# S6E1B3xG register map
Vendor: Cypress; File version: 2.1
CPU: CM0PLUS r0p1, little endian, no MPU, no FPU, 2 interrupt priority bits
Registers are 8-bit, read-write, reset 0x0 unless marked. A register's access mark holds for its fields unless they carry their own. Offsets are from the block's base; [hi:lo] are bit positions; {n}, {i} and the like mark numbered series.

## USBCLK — USB/Ethernet Clock
Base 0x40036000
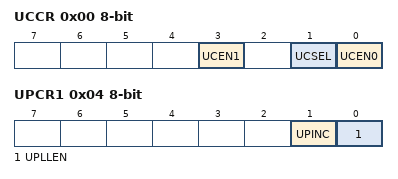
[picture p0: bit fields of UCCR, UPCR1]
0x00 UCCR — USB Clock Control Register [BHW]
  [3] UCEN1 — USB1 clock output enable bit
  [1] UCSEL — USB clock selection bit
  [0] UCEN0 — USB0 clock output enable bit
0x04 UPCR1 — USB-PLL Control Register 1 [BHW]
  [1] UPINC — USB-PLL input clock selection bit
  [0] UPLLEN — USB-PLL oscillation enable bit
0x08 UPCR2 — USB-PLL Control Register 2 [BHW]
  [2:0] UPOWT — USB-PLL oscillation stabilization wait time setting bit
0x0C UPCR3 — USB-PLL Control Register 3 [BHW]
  [4:0] UPLLK — Frequency division ratio (K) setting bit of the USB-PLL clock
0x10 UPCR4 reset 0x3B — USB-PLL Control Register 4 [BHW]
  [6:0] UPLLN — Frequency division ratio (N) setting bit of the USB-PLL clock
0x14 UP_STR ro — USB-PLL Status Register [BHW]
  [0] UPRDY — USB-PLL oscillation stabilization bit
0x18 UPINT_ENR — USB-PLL Interrupt Factor Enable Register [BHW]
  [0] UPCSE — USB-PLL oscillation stabilization wait complete interrupt enable bit
0x1C UPINT_CLR wo — USB-PLL Interrupt Factor Clear Register [BHW]
  [0] UPCSC — USB-PLL oscillation stabilization interrupt factor clear bit
0x20 UPINT_STR ro — USB-PLL Interrupt Factor Status Register [BHW]
  [0] UPCSI — USB-PLL interrupt factor status bit
0x24 UPCR5 reset 0x4 — USB-PLL Control Register 5 [BHW]
  [3:0] UPLLM — Frequency division ratio (M) setting bit of the USB-PLL clock
0x30 USBEN0 reset 0x4 — USB0 Enable Register [BHW]
  [0] USBEN0 — USB0 enable bit
0x34 USBEN1 reset 0x4 — USB1 Enable Register [BHW]
  [0] USBEN1 — USB1 enable bit

## CRC — CRC Registers
Base 0x40039000
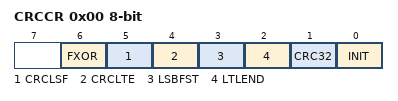
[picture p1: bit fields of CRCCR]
0x00 CRCCR — CRC Control Register [BHW]
  [6] FXOR — Final XOR control bit
  [5] CRCLSF — CRC result bit-order setting bit
  [4] CRCLTE — CRC result byte-order setting bit
  [3] LSBFST — Bit-order setting bit
  [2] LTLEND — Byte-order setting bit
  [1] CRC32 — CRC mode selection bit
  [0] INIT — Initialization bit
0x04 CRCINIT 32-bit reset 0xFFFFFFFF — Initial Value Register [BHW]
  [31:0] D — Initial value bits
0x08 CRCIN 32-bit — Input Data Register [BHW]
  [31:0] D — Input data bits
0x0C CRCR 32-bit ro reset 0xFFFFFFFF — CRC Register [BHW]
  [31:0] D — CRC bits

## WC — Watch Counter
Base 0x4003A000
0x00 WCRD ro — Watch Counter Read Register [BHW]
  [5:0] CTR — Counter read bits
0x01 WCRL — Watch Counter Reload Register [BHW]
  [5:0] RLC — Counter reload value setting bits
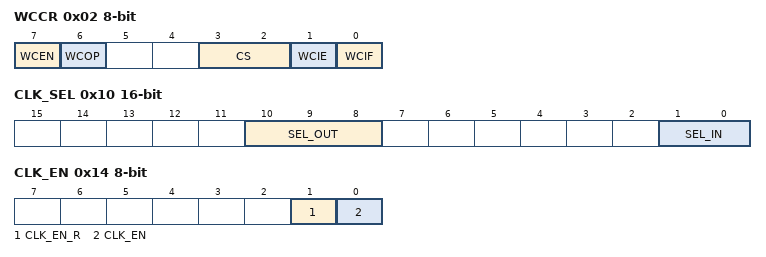
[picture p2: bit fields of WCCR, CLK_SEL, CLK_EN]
0x02 WCCR — Watch Counter Control Register [BHW]
  [7] WCEN — Watch counter operation enable bit
  [6] WCOP ro — Watch counter operating state flag
  [3:2] CS — Count clock select bits
  [1] WCIE — Interrupt request enable bit
  [0] WCIF — Interrupt request flag bit
0x10 CLK_SEL 16-bit — Clock Selection Register [BHW]
  [10:8] SEL_OUT — Output clock selection bit
  [1:0] SEL_IN — Input clock selection bit
0x14 CLK_EN — Division Clock Enable Register [BHW]
  [1] CLK_EN_R — Division clock enable read bit
  [0] CLK_EN — Division clock enable bit

## LSCRP — Low-speed CR Prescaler Register
Base 0x4003C000
0x00 LCR_PRSLD — Low-speed CR Prescaler Control Register [BHW]
  [5:0] LCR_PRSLD — Low-speed CR Prescaler Load

## MFSI2S0 — I2S0 Registers
Base 0x4003CA00
Same registers: MFSI2S1 0x4003CA80
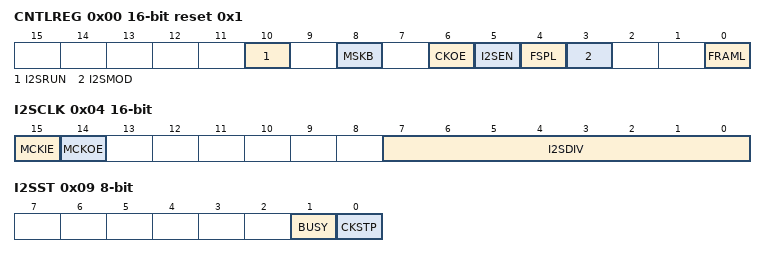
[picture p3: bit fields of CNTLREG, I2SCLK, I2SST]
0x00 CNTLREG 16-bit reset 0x1 — Control Register [HW]
  [10] I2SRUN — I2S clock generate enable bit
  [8] MSKB — Mask bit output bit
  [6] CKOE — I2SCK and I2SWS output enable bit
  [5] I2SEN — I2S mode enable bit
  [4] FSPL — I2SWS polarity set bit
  [3] I2SMOD — I2S mode select bit
  [0] FRAML — Frame length select bit
0x04 I2SCLK 16-bit — I2S Clock Register [HW]
  [15] MCKIE — Main clock input enable bit
  [14] MCKOE — Main clock output enable bit
  [7:0] I2SDIV — I2S clock division set bit
0x08 I2SRST wo — I2S Reset Register [B]
  [7:0] I2SRST — I2S software reset bit
0x09 I2SST ro — I2S Status Register [B]
  [1] BUSY — Bus busy indication for transmit bit
  [0] CKSTP — Clock stop indication bit

## DSTC — DSTC registers
Base 0x40061000
0x00 DESTP 32-bit — Descriptor top address Register [BHW]
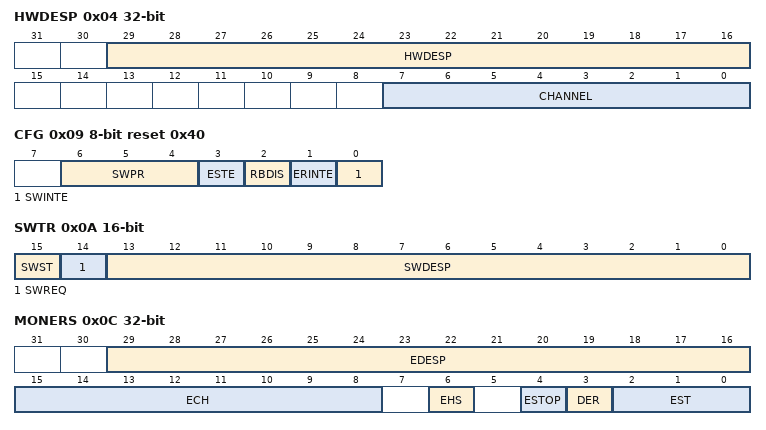
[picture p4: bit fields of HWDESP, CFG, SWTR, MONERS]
0x04 HWDESP 32-bit — Hardware DES pointer Register [BHW]
  [29:16] HWDESP, [7:0] CHANNEL
0x08 CMD reset 0x1 — Command Register [B]
0x09 CFG reset 0x40 — Configuration Register [B]
  [6:4] SWPR — Software transfer priority
  [3] ESTE — Error stop enable
  [2] RBDIS — Read skip buffer disable
  [1] ERINTE — Error interrupt enable
  [0] SWINTE — Software interrupt enable
0x0A SWTR 16-bit — Software trigger Register [H]
  [15] SWST ro — Software status
  [14] SWREQ ro — Software request
  [13:0] SWDESP — Software DES pointer
0x0C MONERS 32-bit — Transfer Error Status Monitor Register [BHW]
  [29:16] EDESP ro — Error DES pointer
  [15:8] ECH ro — Error hardware channel
  [6] EHS ro — Error hardware software
  [4] ESTOP ro — Error stop
  [3] DER ro — Double error
  [2:0] EST ro — Error status
{0x10+4i} DREQENB{i} 32-bit (i=0..7) — DMA request enable Register {i} [BHW]
{0x30+4i} HWINT{i} 32-bit (i=0..7) — Hardware transfer interrupt Register {i} [BHW]
{0x50+4i} HWINTCLR{i} 32-bit (i=0..7) — Hardware transfer interrupt clear Register {i} [BHW]
{0x70+4i} DQMSK{i} 32-bit (i=0..7) — DMA request mask Register {i} [BHW]
{0x90+4i} DQMSKCLR{i} 32-bit (i=0..7) — DMA request mask clear Register {i} [BHW]

## MTB_DWT — Micro Trace Buffer Data Watchpoint and Trace Registers
Base 0xF0001000
0x00 CMP_ADDR_START 32-bit — MTB_DWT Address Compare Start trace Register [BHW]
  [31:0] ADCMP_STA — MTB_DWT address comparison start trace bits
0x04 CMP_DATA_START 32-bit — MTB_DWT Data Compare Start trace Register [BHW]
  [31:0] DTCMP_STA — MTB_DWT data comparison start trace bits
0x08 CMP_MASK_START 32-bit — MTB_DWT Mask Data Compare Start Trace Register [BHW]
  [31:0] MSK_STA — MTB_DWT data compare start trace register mask bits
0x10 CMP_ADDR_STOP 32-bit — MTB_DWT Address Compare Stop trace Register [BHW]
  [31:0] ADCMP_STO — MTB_DWT address comparison stop trace bits
0x14 CMP_DATA_STOP 32-bit — MTB_DWT Data Compare Stop trace Register [BHW]
  [31:0] DTCMP_STO — MTB_DWT data comparison stop trace bits
0x18 CMP_MASK_STOP 32-bit — MTB_DWT Mask Data Compare Stop Trace Register [BHW]
  [31:0] MSK_STO — MTB_DWT data compare stop trace register mask bits
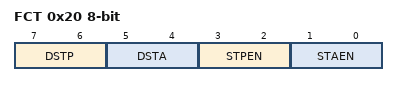
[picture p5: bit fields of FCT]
0x20 FCT — MTB_DWT Function Register [BHW]
  [7:6] DSTP — Data size stop bits
  [5:4] DSTA — Data size start bits
  [3:2] STPEN — Enable MTB_DWT stop MTB function bits
  [1:0] STAEN — Enable MTB_DWT start MTB function bits
{0xFC0+4i} PID{i} 32-bit ro (i=4..7) — Peripheral ID{i} Register [BHW]
  [31:0] PERID — Peripheral ID bits
0xFE0 PID0 32-bit ro reset 0x16 — Peripheral ID0 Register [BHW]
  [31:0] PERID — Peripheral ID bits
0xFE4 PID1 32-bit ro reset 0x48 — Peripheral ID1 Register [BHW]
  [31:0] PERID — Peripheral ID bits
0xFE8 PID2 32-bit ro reset 0x8 — Peripheral ID2 Register [BHW]
  [31:0] PERID — Peripheral ID bits
0xFEC PID3 32-bit ro — Peripheral ID3 Register [BHW]
  [31:0] PERID — Peripheral ID bits
0xFF0 CID0 32-bit ro reset 0xD — Component ID0 Register [BHW]
  [31:0] CPNTID — Component ID bits
0xFF4 CID1 32-bit ro reset 0x90 — Component ID1 Register [BHW]
  [31:0] CPNTID — Component ID bits
0xFF8 CID2 32-bit ro reset 0x5 — Component ID2 Register [BHW]
  [31:0] CPNTID — Component ID bits
0xFFC CID3 32-bit ro reset 0xB1 — Component ID3 Register [BHW]
  [31:0] CPNTID — Component ID bits
